AUTOSAR XML (schema 4.0)
package /ComplexDrivers
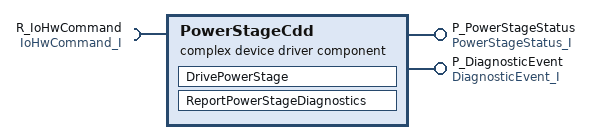
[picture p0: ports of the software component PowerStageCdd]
  complex device driver sw component type PowerStageCdd
    require port R_IoHwCommand: required-interface=IoHwCommand_I
    provide port P_PowerStageStatus: provided-interface=PowerStageStatus_I
    provide port P_DiagnosticEvent: provided-interface=DiagnosticEvent_I
    behavior PowerStageCdd_IB
      runnable DrivePowerStage
      runnable ReportPowerStageDiagnostics
